# SIM3U167_B register map
File version: 1
USB, 256K Flash, 32K RAM, EMIF
CPU: 
Registers are 32-bit, read-write, reset 0x0 unless marked. A register's access mark holds for its fields unless they carry their own. Offsets are from the block's base; lines under a group give offsets from that group; [hi:lo] are bit positions; {n}, {i} and the like mark numbered series; 'fields as' and 'values as' point back to an identical list; <NAME> marks a mode.

## Memory map
0x40000000 USART_0 size 0xFFC
0x40001000 USART_1 size 0xFFC
0x40002000 UART_0 size 0xFFC
0x40003000 UART_1 size 0xFFC
0x40004000 SPI_0 size 0xFFC
0x40005000 SPI_1 size 0xFFC
0x40006000 SPI_2 size 0xFFC
0x40009000 I2C_0 size 0xFFC
0x4000A000 I2C_1 size 0xFFC
0x4000E000 EPCA_0 size 0xFFC
0x4000F000 PCA_0 size 0xFFC
0x40010000 PCA_1 size 0xFFC
0x40014000 TIMER_0 size 0xFFC
0x40015000 TIMER_1 size 0xFFC
0x40018000 USB_0 size 0xFFC
0x4001A000 SARADC_0 size 0xFFC
0x4001B000 SARADC_1 size 0xFFC
0x4001E000 SSG_0 size 0xFFC
0x4001F000 CMP_0 size 0xFFC
0x40020000 CMP_1 size 0xFFC
0x40023000 CAPSENSE_0 size 0xFFC
0x40026000 EMIF_0 size 0xFFC
0x40027000 AES_0 size 0xFFC
0x40028000 CRC_0 size 0xFFC
0x40029000 RTC_0 size 0xFFC
0x4002A000 PBCFG_0 size 0xFFC
0x4002A0A0 PBSTD_0 size 0xFFC
0x4002A140 PBSTD_1 size 0xFFC
0x4002A1E0 PBSTD_2 size 0xFFC
0x4002A320 PBSTD_3 size 0xFFC
0x4002A3C0 PBHD_4 size 0xFFC
0x4002D000 CLKCTRL_0 size 0xFFC
0x4002D060 RSTSRC_0 size 0xFFC
0x4002E000 FLASHCTRL_0 size 0xFFC
0x4002F000 VMON_0 size 0xFFC
0x40030000 WDTIMER_0 size 0xFFC
0x40031000 IDAC_0 size 0xFFC
0x40032000 IDAC_1 size 0xFFC
0x40036000 DMACTRL_0 size 0xFFC
0x40037000 DMAXBAR_0 size 0xFFC
0x40038000 LPTIMER_0 size 0xFFC
0x40039000 LDO_0 size 0xFFC
0x40039010 VREF_0 size 0xFFC
0x4003A000 I2S_0 size 0xFFC
0x4003B000 PLL_0 size 0xFFC
0x4003C000 EXTOSC_0 size 0xFFC
0x40040000 VREG_0 size 0xFFC
0x40041000 LPOSC_0 size 0xFFC
0x40042000 EXTVREG_0 size 0xFFC
0x40044000 IVC_0 size 0xFFC
0x40048000 PMU_0 size 0xFFC
0x40049000 LOCK_0 size 0xFFC
0x400490C0 DEVICEID_0 size 0xFFC

## Interrupts
0 WDTIMER_IRQn (WDTIMER_0)
1 PBEXT0_IRQn (PBCFG_0)
2 PBEXT1_IRQn (PBCFG_0)
3 RTCALRM_IRQn (RTC_0)
{n+4} DMACH{n}_IRQn (DMAXBAR_0) (n=0..15)
20 TIMER0L_IRQn (TIMER_0)
21 TIMER0H_IRQn (TIMER_0)
22 TIMER1L_IRQn (TIMER_1)
23 TIMER1H_IRQn (TIMER_1)
24 EPCA0_IRQn (EPCA_0)
25 PCA0_IRQn (PCA_0)
26 PCA1_IRQn (PCA_1)
27 USART0_IRQn (USART_0)
28 USART1_IRQn (USART_1)
29 SPI0_IRQn (SPI_0)
30 SPI1_IRQn (SPI_1)
31 SPI2_IRQn (SPI_2)
32 I2C0_IRQn (I2C_0)
33 I2C1_IRQn (I2C_1)
34 USB0_IRQn (USB_0)
35 SARADC0_IRQn (SARADC_0)
36 SARADC1_IRQn (SARADC_1)
37 CMP0_IRQn (CMP_0)
38 CMP1_IRQn (CMP_1)
39 CAPSENSE0_IRQn (CAPSENSE_0)
40 I2S0RX_IRQn (I2S_0)
41 I2S0TX_IRQn (I2S_0)
42 AES0_IRQn (AES_0)
43 VDDLOW_IRQn (VMON_0)
44 RTCFAIL_IRQn (RTC_0)
45 PMATCH_IRQn (PBCFG_0)
46 UART0_IRQn (UART_0)
47 UART1_IRQn (UART_1)
48 IDAC0_IRQn (IDAC_0)
49 IDAC1_IRQn (IDAC_1)
50 LPTIMER0_IRQn (LPTIMER_0)
51 PLL_IRQn (PLL_0)
52 VREGDROPOUT_IRQn (VREG_0)
53 VREGLOW_IRQn (VMON_0)

## CRC_0
Base 0x40028000
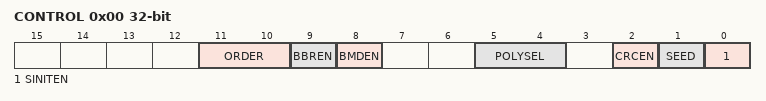
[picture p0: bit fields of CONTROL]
0x00 CONTROL — Module Control
  [11:10] ORDER — Input Processing Order.
    0=NO_REORDER (No byte reorientation (output is same order as input).); 1=BIG_ENDIAN_16 (Swap for 16-bit big endian order (input: B3 B2 B1 B0, output: B2 B3 B0 B1).); 2=BIG_ENDIAN_32 (Swap for 32-bit big endian order (input: B3 B2 B1 B0, output: B0 B1 B2 B3).)
  [9] BBREN — Byte-Level Bit Reversal Enable.
    0=DISABLED (No byte-level bit reversal (input is same order as written).); 1=ENABLED (Byte-level bit reversal enabled (the bits in each byte are reversed).)
  [8] BMDEN — Byte Mode Enable.
    0=DISABLED (Disable byte mode (word/byte width is determined automatically by the hardware).); 1=ENABLED (Enable byte mode (all writes are considered as bytes).)
  [5:4] POLYSEL — Polynomial Selection.
    0=CRC_32_04C11DB7 (Select 32-bit polynomial: 0x04C11DB7.); 1=CRC_16_1021 (Select 16-bit polynomial: 0x1021.); 2=CRC_16_3D65 (Select 16-bit polynomial: 0x3D65.); 3=CRC_16_8005 (Select 16-bit polynomial: 0x8005.)
  [2] CRCEN — CRC Enable.
    0=DISABLED (Disable CRC operations.); 1=ENABLED (Enable CRC operations.)
  [1] SEED wo — Seed Setting.
    0=ALL_ZEROES (CRC seed value is all 0's (0x00000000)); 1=ALL_ONES (CRC seed value is all 1's (0xFFFFFFFF).)
  [0] SINITEN wo — Seed Initialization Enable.
    0=DISABLED (Do not initialize the CRC module to the value set by the SEED bit.); 1=ENABLED (Initialize the CRC module to the value set by the SEED bit.)
0x10 DATA reset 0xFFFFFFFF read-has-side-effects — Input/Result Data
  [31:0] DATA — Input/Result Data.
0x20 RDATA reset 0xFFFFFFFF — Bit-Reversed Output Data
  [31:0] RDATA ro — Bit-Reversed Output Data.
